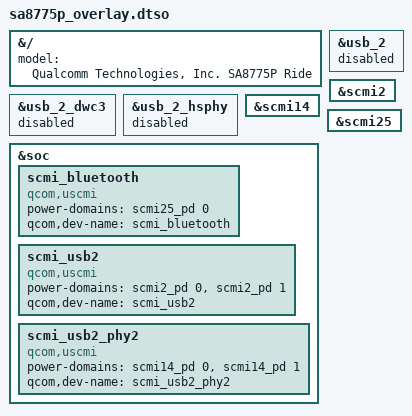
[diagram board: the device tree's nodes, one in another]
// SPDX-License-Identifier: BSD-3-Clause
/*
 * Copyright (c) 2023-2024 Qualcomm Innovation Center, Inc. All rights reserved.
 * Copyright (c) 2023, Linaro Limited
 */

/dts-v1/;
/plugin/;

#include "sa8255p_overlay.dtsi"
#include "sa8775p-vms.dtsi"

&{/} {
	model = "Qualcomm Technologies, Inc. SA8775P Ride";
};

&usb_2 {
	status = "disabled";
};

&usb_2_dwc3 {
	status = "disabled";
};

&usb_2_hsphy {
	status = "disabled";
};

&scmi2 {
	status = "okay";
};

&scmi14 {
	status = "okay";
};

&scmi25 {
	status = "okay";
};

&soc {
	scmi_bluetooth {
		compatible = "qcom,uscmi";

		power-domains = <&scmi25_pd 0>;
		power-domain-names = "power";

		qcom,dev-name = "scmi_bluetooth";
	};

	scmi_usb2 {
		compatible = "qcom,uscmi";

		power-domains = <&scmi2_pd 0>, <&scmi2_pd 1>;
		power-domain-names = "usb_transfer", "usb_core";

		qcom,dev-name = "scmi_usb2";
	};

	scmi_usb2_phy2 {
		compatible = "qcom,uscmi";

		power-domains = <&scmi14_pd 0>, <&scmi14_pd 1>;
		power-domain-names = "usb_transfer", "usb_core";

		qcom,dev-name = "scmi_usb2_phy2";
	};
};
